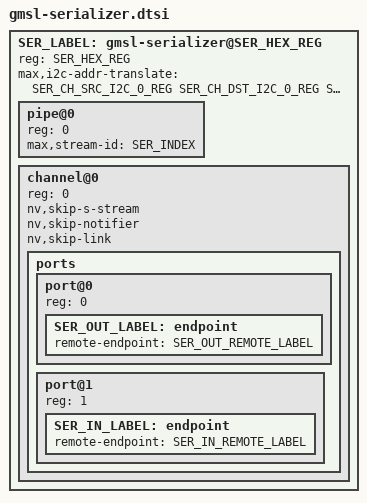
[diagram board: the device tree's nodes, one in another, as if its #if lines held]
#ifndef SER_COMPAT
#define SER_COMPAT "maxim,max96717"
#endif

#ifndef SER_HEX_REG
#define SER_HEX_REG 0x40
#endif

#ifdef SER_INDEX
#define SER_LABEL CONCAT(serializer, SER_INDEX)
#define SER_OUT_LABEL CONCAT(ser_out, SER_INDEX)
#define SER_IN_LABEL CONCAT(ser_in, SER_INDEX)
#define SER_OUT_REMOTE_LABEL CONCAT(deser_in, SER_INDEX)
#define SER_IN_REMOTE_LABEL CONCAT(ox03a_out, SER_INDEX)
#endif

#if !defined(SER_LABEL)
#error
#endif

#if !defined(SER_OUT_LABEL)
#error
#endif

#if !defined(SER_IN_LABEL)
#error
#endif

#if !defined(SER_OUT_REMOTE_LABEL)
#error
#endif

#if !defined(SER_IN_REMOTE_LABEL)
#error
#endif

SER_LABEL: gmsl-serializer@SER_HEX_REG {
	#address-cells = <1>;
	#size-cells = <0>;

	compatible = SER_COMPAT;
	reg = <SER_HEX_REG>;

#if (defined(SER_CH_SRC_I2C_0_REG) && defined(SER_CH_DST_I2C_0_REG)) || \
    (defined(SER_CH_SRC_I2C_1_REG) && defined(SER_CH_DST_I2C_1_REG))

#if !defined(SER_CH_SRC_I2C_0_REG) && !defined(SER_CH_DST_I2C_0_REG)
#define SER_CH_SRC_I2C_0_REG
#define SER_CH_DST_I2C_0_REG
#endif

#if !defined(SER_CH_SRC_I2C_1_REG) && !defined(SER_CH_DST_I2C_1_REG)
#define SER_CH_SRC_I2C_1_REG
#define SER_CH_DST_I2C_1_REG
#endif

	max,i2c-addr-translate = <
		SER_CH_SRC_I2C_0_REG SER_CH_DST_I2C_0_REG
		SER_CH_SRC_I2C_1_REG SER_CH_DST_I2C_1_REG
	>;
#endif

	pipe@0 {
		reg = <0>;

		max,stream-id = <SER_INDEX>;
	};

	channel@0 {
		reg = <0>;

		nv,skip-s-stream;
		nv,skip-notifier;
		nv,skip-link;

		ports {
			#address-cells = <1>;
			#size-cells = <0>;

			port@0 {
				reg = <0>;

				SER_OUT_LABEL: endpoint {
					remote-endpoint = <&SER_OUT_REMOTE_LABEL>;
				};
			};

			port@1 {
				reg = <1>;

				SER_IN_LABEL: endpoint {
					remote-endpoint = <&SER_IN_REMOTE_LABEL>;
				};
			};
		};
	};
};

#undef SER_CH_SRC_I2C_0_REG
#undef SER_CH_DST_I2C_0_REG
#undef SER_CH_SRC_I2C_1_REG
#undef SER_CH_DST_I2C_1_REG
#undef SER_COMPAT
#undef SER_HEX_REG
#undef SER_INDEX
#undef SER_LABEL
#undef SER_OUT_LABEL
#undef SER_IN_LABEL
#undef SER_OUT_REMOTE_LABEL
#undef SER_IN_REMOTE_LABEL
